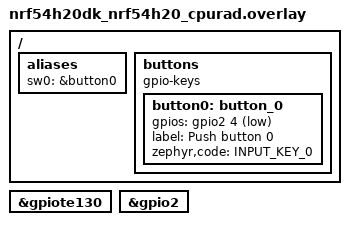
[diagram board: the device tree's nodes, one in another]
/*
 * Copyright (c) 2025 Nordic Semiconductor ASA
 *
 * SPDX-License-Identifier: LicenseRef-Nordic-5-Clause
 */

/ {
	aliases {
		sw0 = &button0;
	};

	/*
	 * Redefine sw0/button0 to use RXD1 - P1.10
	 * Thus, when sending character from host, there will be gpio interrupt,
	 * the same as originally triggered by sw0 button.
	 */
	buttons {
		compatible = "gpio-keys";

		button0: button_0 {
			gpios = <&gpio2 4 (GPIO_PULL_UP | GPIO_ACTIVE_LOW)>;
			label = "Push button 0";
			zephyr,code = <INPUT_KEY_0>;
		};
	};
};

&gpiote130 {
	status = "okay";
};

&gpio2 {
	status = "okay";
};
